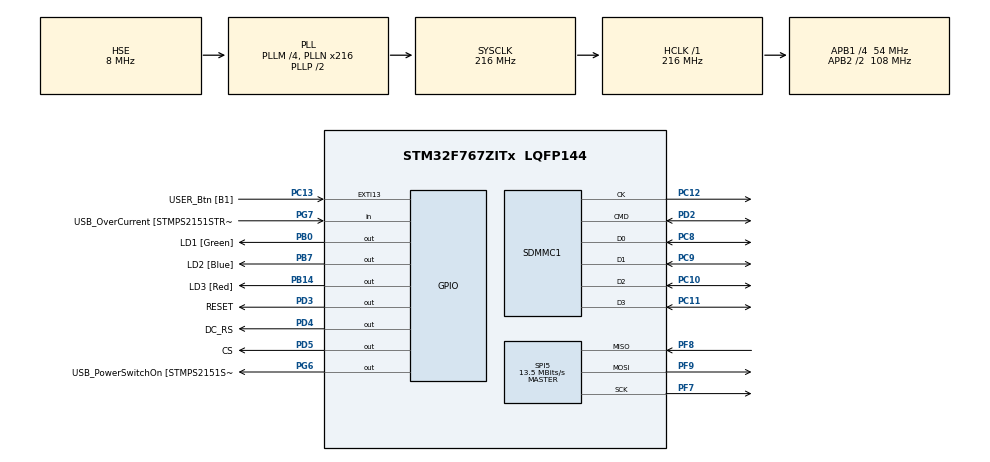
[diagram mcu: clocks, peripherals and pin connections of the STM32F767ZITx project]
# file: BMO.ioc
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CORTEX_M7.default_mode_Activation=1
Mcu.Family=STM32F7
Mcu.Name=STM32F767ZITx
Mcu.Package=LQFP144
NVIC.PriorityGroup=NVIC_PRIORITYGROUP_4
NVIC.TIM7_IRQn=true\:0\:0\:false\:false\:true\:true\:true\:false
PA1.GPIO_Label=RMII_REF_CLK [LAN8742A-CZ-TR_REFCLK0]
PA1.Signal=ETH_REF_CLK
PA10.GPIO_Label=USB_ID
PA10.Signal=USB_OTG_FS_ID
PA11.GPIO_Label=USB_DM
PA11.Signal=USB_OTG_FS_DM
PA12.GPIO_Label=USB_DP
PA12.Signal=USB_OTG_FS_DP
PA13.GPIO_Label=TMS
PA13.Signal=SYS_JTMS-SWDIO
PA14.GPIO_Label=TCK
PA14.Signal=SYS_JTCK-SWCLK
PA2.GPIO_Label=RMII_MDIO [LAN8742A-CZ-TR_MDIO]
PA2.Signal=ETH_MDIO
PA7.GPIO_Label=RMII_CRS_DV [LAN8742A-CZ-TR_CRS_DV]
PA7.Signal=ETH_CRS_DV
PA8.GPIO_Label=USB_SOF [TP1]
PA8.Signal=USB_OTG_FS_SOF
PA9.GPIO_Label=USB_VBUS
PA9.Signal=USB_OTG_FS_VBUS
PB0.GPIO_Label=LD1 [Green]
PB0.Signal=GPIO_Output
PB13.GPIO_Label=RMII_TXD1 [LAN8742A-CZ-TR_TXD1]
PB13.Signal=ETH_TXD1
PB14.GPIO_Label=LD3 [Red]
PB14.Signal=GPIO_Output
PB3.GPIO_Label=SW0
PB3.Signal=SYS_JTDO-SWO
PB7.GPIO_Label=LD2 [Blue]
PB7.Signal=GPIO_Output
PC1.GPIO_Label=RMII_MDC [LAN8742A-CZ-TR_MDC]
PC1.Signal=ETH_MDC
PC10.Mode=SD_4_bits_Wide_bus
PC10.Signal=SDMMC1_D2
PC11.Mode=SD_4_bits_Wide_bus
PC11.Signal=SDMMC1_D3
PC12.Mode=SD_4_bits_Wide_bus
PC12.Signal=SDMMC1_CK
PC13.GPIO_Label=USER_Btn [B1]
PC13.Signal=GPXTI13
PC14/OSC32_IN.Signal=RCC_OSC32_IN
PC15/OSC32_OUT.Signal=RCC_OSC32_OUT
PC4.GPIO_Label=RMII_RXD0 [LAN8742A-CZ-TR_RXD0]
PC4.Signal=ETH_RXD0
PC5.GPIO_Label=RMII_RXD1 [LAN8742A-CZ-TR_RXD1]
PC5.Signal=ETH_RXD1
PC8.Mode=SD_4_bits_Wide_bus
PC8.Signal=SDMMC1_D0
PC9.Mode=SD_4_bits_Wide_bus
PC9.Signal=SDMMC1_D1
PD0.Signal=FMC_D2_DA2
PD1.Signal=FMC_D3_DA3
PD2.Mode=SD_4_bits_Wide_bus
PD2.Signal=SDMMC1_CMD
PD3.GPIO_Label=RESET
PD3.PinState=GPIO_PIN_SET
PD3.Signal=GPIO_Output
PD4.GPIO_Label=DC_RS
PD4.Signal=GPIO_Output
PD5.GPIO_Label=CS
PD5.PinState=GPIO_PIN_SET
PD5.Signal=GPIO_Output
PF7.Mode=Full_Duplex_Master
PF7.Signal=SPI5_SCK
PF8.Mode=Full_Duplex_Master
PF8.Signal=SPI5_MISO
PF9.Mode=Full_Duplex_Master
PF9.Signal=SPI5_MOSI
PG11.GPIO_Label=RMII_TX_EN [LAN8742A-CZ-TR_TXEN]
PG11.Signal=ETH_TX_EN
PG13.GPIO_Label=RMII_TXD0 [LAN8742A-CZ-TR_TXD0]
PG13.Signal=ETH_TXD0
PG6.GPIO_Label=USB_PowerSwitchOn [STMPS2151STR_EN]
PG6.Signal=GPIO_Output
PG7.GPIO_Label=USB_OverCurrent [STMPS2151STR_FAULT]
PG7.Signal=GPIO_Input
PH0/OSC_IN.GPIO_Label=MCO [STM32F103CBT6_PA8]
PH0/OSC_IN.Mode=HSE-External-Clock-Source
PH0/OSC_IN.Signal=RCC_OSC_IN
PH1/OSC_OUT.Mode=HSE-External-Clock-Source
PH1/OSC_OUT.Signal=RCC_OSC_OUT
ProjectManager.HeapSize=0x200
ProjectManager.StackSize=0x400
ProjectManager.TargetToolchain=STM32CubeIDE
RCC.48MHZClocksFreq_Value=24000000
RCC.AHBFreq_Value=216000000
RCC.APB1CLKDivider=RCC_HCLK_DIV4
RCC.APB1Freq_Value=54000000
RCC.APB1TimFreq_Value=108000000
RCC.APB2CLKDivider=RCC_HCLK_DIV2
RCC.APB2Freq_Value=108000000
RCC.APB2TimFreq_Value=216000000
RCC.CortexFreq_Value=216000000
RCC.HCLKFreq_Value=216000000
RCC.HSE_VALUE=8000000
RCC.HSI_VALUE=16000000
RCC.LSE_VALUE=32768
RCC.PLLM=4
RCC.PLLMUL=RCC_PLL_MUL9
RCC.PLLN=216
RCC.PLLQ=9
RCC.PLLSourceVirtual=RCC_PLLSOURCE_HSE
RCC.PRESCALERUSB=RCC_USBCLKSOURCE_PLL_DIV1_5
RCC.SDMMCClockSelection=RCC_SDMMC1CLKSOURCE_CLK48
RCC.SYSCLKFreq_VALUE=216000000
RCC.SYSCLKSource=RCC_SYSCLKSOURCE_PLLCLK
RCC.SYSCLKSourceVirtual=RCC_SYSCLKSOURCE_PLLCLK
RCC.USBFreq_Value=48000000
RCC.VCOOutputFreq_Value=432000000
SDMMC1.ClockDiv=4
SH.FMC_D2_DA2.0=FMC_D2
SH.FMC_D3_DA3.0=FMC_D3
SPI5.BaudRatePrescaler=SPI_BAUDRATEPRESCALER_8
SPI5.CalculateBaudRate=13.5 MBits/s
SPI5.DataSize=SPI_DATASIZE_8BIT
SPI5.Direction=SPI_DIRECTION_2LINES
SPI5.Mode=SPI_MODE_MASTER
SPI5.NSSPMode=SPI_NSS_PULSE_DISABLE
SPI5.VirtualType=VM_MASTER
TIM7.Period=999
TIM7.Prescaler=107
VP_DMA2D_VS_DMA2D.Mode=DMA2D_Activate
VP_TIM7_VS_ClockSourceINT.Mode=Enable_Timer
board=NUCLEO-F767ZI

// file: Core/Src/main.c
/* USER CODE BEGIN Header */
/**
  ******************************************************************************
  * @file           : main.c
  * @brief          : Main program body
  ******************************************************************************
  * @attention
  *
  * Copyright (c) 2026 STMicroelectronics.
  * All rights reserved.
  *
  * This software is licensed under terms that can be found in the LICENSE file
  * in the root directory of this software component.
  * If no LICENSE file comes with this software, it is provided AS-IS.
  *
  ******************************************************************************
  */
/* USER CODE END Header */

#include "main.h"
#include "dma2d.h"
#include "sdmmc.h"
#include "spi.h"
#include "tim.h"
#include "gpio.h"

/* USER CODE BEGIN Includes */
#include "bmo_state.h"
#include "bmo_input.h"
#include "face_gfx.h"
#include "bmo_face.h"
#include "bmo_p4_adapter.h"
/* USER CODE END Includes */

void SystemClock_Config(void);
static void MPU_Config(void);

int main(void)
{

  /* MPU Configuration--------------------------------------------------------*/
  MPU_Config();

  /* MCU Configuration--------------------------------------------------------*/

  /* Reset of all peripherals, Initializes the Flash interface and the SysTick. */
  HAL_Init();

  /* Configure the system clock */
  SystemClock_Config();

  /* Initialize all configured peripherals */
  MX_GPIO_Init();
  MX_DMA2D_Init();
  MX_SDMMC1_SD_Init();
  MX_TIM7_Init();
  MX_SPI5_Init();

  /* USER CODE BEGIN 2 */

  /* Initialize LCD through SPI5 */
  gfx_init();

  /* Initialize P2 Face Renderer */
  face_init(HAL_GetTick());

  /* Initialize P3 Input Handler */
  bmo_input_init();

  /* Initialize P3 State Machine */
  bmo_state_init();

  /* Register P4 Snake and Simon */
  bmo_p4_adapter_register();

  /* Synchronize state timer with system time */
  bmo_state_tick(HAL_GetTick());

  /* USER CODE END 2 */

  /* Infinite loop */
  while (1)
  {

    /* USER CODE BEGIN 3 */

    /* Get current system time */
    uint32_t now_ms = HAL_GetTick();

    /* Update P3 State Machine timers */
    bmo_state_tick(now_ms);

    /* Update P2 face animation */
    face_tick(now_ms);

  }
  /* USER CODE END 3 */
}

void SystemClock_Config(void)
{
  RCC_OscInitTypeDef RCC_OscInitStruct = {0};
  RCC_ClkInitTypeDef RCC_ClkInitStruct = {0};

  /** Initializes the CPU, AHB and APB buses clocks
  */
  __HAL_RCC_PWR_CLK_ENABLE();
  __HAL_PWR_VOLTAGESCALING_CONFIG(PWR_REGULATOR_VOLTAGE_SCALE1);

  /** Initializes the RCC Oscillators
  */
  RCC_OscInitStruct.OscillatorType = RCC_OSCILLATORTYPE_HSE;
  RCC_OscInitStruct.HSEState = RCC_HSE_BYPASS;
  RCC_OscInitStruct.PLL.PLLState = RCC_PLL_ON;
  RCC_OscInitStruct.PLL.PLLSource = RCC_PLLSOURCE_HSE;
  RCC_OscInitStruct.PLL.PLLM = 4;
  RCC_OscInitStruct.PLL.PLLN = 216;
  RCC_OscInitStruct.PLL.PLLP = RCC_PLLP_DIV2;
  RCC_OscInitStruct.PLL.PLLQ = 9;
  RCC_OscInitStruct.PLL.PLLR = 2;

  if (HAL_RCC_OscConfig(&RCC_OscInitStruct) != HAL_OK)
  {
    Error_Handler();
  }

  /** Activate the Over-Drive mode
  */
  if (HAL_PWREx_EnableOverDrive() != HAL_OK)
  {
    Error_Handler();
  }

  /** Initializes the CPU, AHB and APB buses clocks
  */
  RCC_ClkInitStruct.ClockType = RCC_CLOCKTYPE_HCLK |
                                RCC_CLOCKTYPE_SYSCLK |
                                RCC_CLOCKTYPE_PCLK1 |
                                RCC_CLOCKTYPE_PCLK2;

  RCC_ClkInitStruct.SYSCLKSource = RCC_SYSCLKSOURCE_PLLCLK;
  RCC_ClkInitStruct.AHBCLKDivider = RCC_SYSCLK_DIV1;
  RCC_ClkInitStruct.APB1CLKDivider = RCC_HCLK_DIV4;
  RCC_ClkInitStruct.APB2CLKDivider = RCC_HCLK_DIV2;

  if (HAL_RCC_ClockConfig(&RCC_ClkInitStruct, FLASH_LATENCY_7) != HAL_OK)
  {
    Error_Handler();
  }
}

/**
  * @brief MPU Configuration
  * @retval None
  */
static void MPU_Config(void)
{
  MPU_Region_InitTypeDef MPU_InitStruct = {0};

  /* Disables the MPU */
  HAL_MPU_Disable();

  /** Initializes and configures the Region 0
  */
  MPU_InitStruct.Enable = MPU_REGION_ENABLE;
  MPU_InitStruct.Number = MPU_REGION_NUMBER0;
  MPU_InitStruct.BaseAddress = 0x0;
  MPU_InitStruct.Size = MPU_REGION_SIZE_4GB;
  MPU_InitStruct.SubRegionDisable = 0x87;
  MPU_InitStruct.TypeExtField = MPU_TEX_LEVEL0;
  MPU_InitStruct.AccessPermission = MPU_REGION_NO_ACCESS;
  MPU_InitStruct.DisableExec = MPU_INSTRUCTION_ACCESS_DISABLE;
  MPU_InitStruct.IsShareable = MPU_ACCESS_SHAREABLE;
  MPU_InitStruct.IsCacheable = MPU_ACCESS_NOT_CACHEABLE;
  MPU_InitStruct.IsBufferable = MPU_ACCESS_NOT_BUFFERABLE;

  HAL_MPU_ConfigRegion(&MPU_InitStruct);

  /* Enables the MPU */
  HAL_MPU_Enable(MPU_PRIVILEGED_DEFAULT);
}

void Error_Handler(void)
{
  __disable_irq();
  while (1)
  {
  }
}
